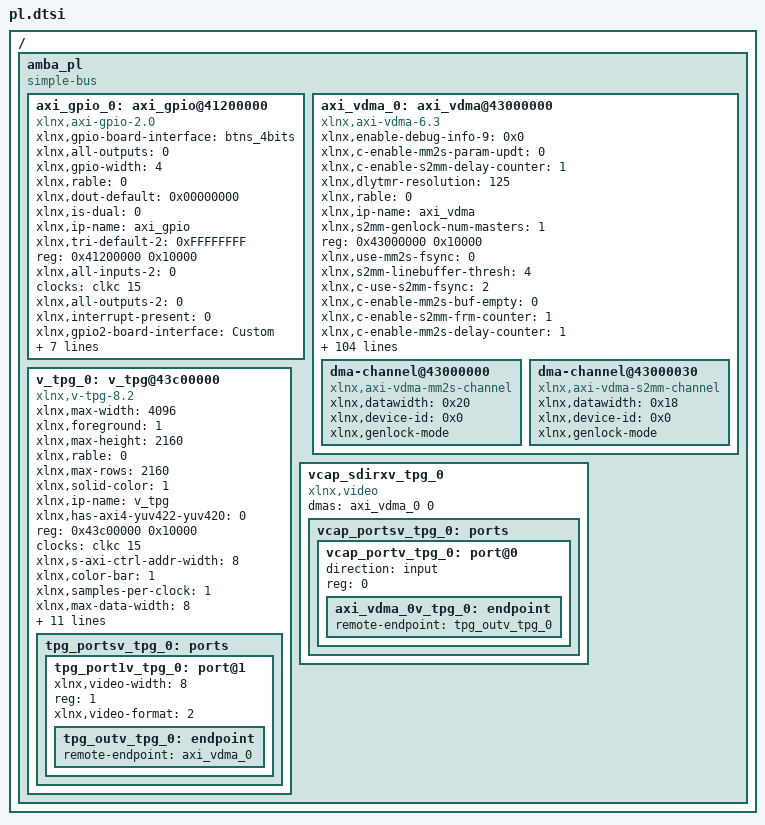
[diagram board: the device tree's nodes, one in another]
/ {
	amba_pl: amba_pl {
		ranges;
		compatible = "simple-bus";
		#address-cells = <1>;
		#size-cells = <1>;
		axi_gpio_0: axi_gpio@41200000 {
			xlnx,gpio-board-interface = "btns_4bits";
			compatible = "xlnx,axi-gpio-2.0" , "xlnx,xps-gpio-1.00.a";
			xlnx,all-outputs = <0>;
			xlnx,gpio-width = <4>;
			xlnx,rable = <0>;
			xlnx,dout-default = <0x00000000>;
			xlnx,is-dual = <0>;
			xlnx,ip-name = "axi_gpio";
			xlnx,tri-default-2 = <0xFFFFFFFF>;
			reg = <0x41200000 0x10000>;
			xlnx,all-inputs-2 = <0>;
			clocks = <&clkc 15>;
			xlnx,all-outputs-2 = <0>;
			xlnx,interrupt-present = <0>;
			xlnx,gpio2-board-interface = "Custom";
			xlnx,edk-iptype = "PERIPHERAL";
			xlnx,dout-default-2 = <0x00000000>;
			xlnx,gpio2-width = <32>;
			status = "okay";
			clock-names = "s_axi_aclk";
			xlnx,use-board-flow;
			xlnx,tri-default = <0xFFFFFFFF>;
			xlnx,name = "axi_gpio_0";
			xlnx,all-inputs = <1>;
		};
		axi_vdma_0: axi_vdma@43000000 {
			xlnx,enable-debug-info-9 = <0x0>;
			xlnx,c-enable-mm2s-param-updt = <0>;
			xlnx,c-enable-s2mm-delay-counter = <1>;
			xlnx,dlytmr-resolution = <125>;
			xlnx,rable = <0>;
			xlnx,ip-name = "axi_vdma";
			xlnx,s2mm-genlock-num-masters = <1>;
			reg = <0x43000000 0x10000>;
			xlnx,use-mm2s-fsync = <0>;
			xlnx,s2mm-linebuffer-thresh = <4>;
			xlnx,c-use-s2mm-fsync = <2>;
			xlnx,c-enable-mm2s-buf-empty = <0>;
			xlnx,c-enable-s2mm-frm-counter = <1>;
			xlnx,c-enable-mm2s-delay-counter = <1>;
			xlnx,c-dlytmr-resolution = <125>;
			xlnx,c-enable-s2mm-buf-full = <0>;
			xlnx,dynamic-resolution = <1>;
			xlnx,s2mm-sof-enable = <0x1>;
			xlnx,mm2s-genlock-num-masters = <1>;
			xlnx,c-s2mm-genlock-num-masters = <1>;
			xlnx,c-enable-s2mm-fsync-out = <0>;
			xlnx,mm2s-linebuffer-thresh = <4>;
			xlnx,c-use-mm2s-fsync = <0>;
			xlnx,c-s2mm-linebuffer-thresh = <4>;
			xlnx,c-enable-mm2s-frm-counter = <1>;
			compatible = "xlnx,axi-vdma-6.3" , "xlnx,axi-vdma-1.00.a";
			xlnx,c-m-axis-mm2s-tdata-width = <32>;
			xlnx,c-enable-all = <0>;
			xlnx,s2mm-max-burst-length = <8>;
			xlnx,c-dynamic-resolution = <1>;
			xlnx,c-enable-s2mm-rst-out = <0>;
			xlnx,mm2s-sof-enable = <1>;
			xlnx,include-s2mm-dre = <0x0>;
			xlnx,c-s2mm-sof-enable = <1>;
			xlnx,c-enable-mm2s-fsync-out = <0>;
			xlnx,c-mm2s-genlock-num-masters = <1>;
			xlnx,c-mm2s-linebuffer-thresh = <4>;
			xlnx,c-enable-tstvec = <0>;
			xlnx,mm2s-max-burst-length = <8>;
			xlnx,c-s2mm-max-burst-length = <8>;
			status = "okay";
			xlnx,c-enable-mm2s-rst-out = <0>;
			xlnx,include-mm2s-dre = <0x0>;
			xlnx,c-include-s2mm-dre = <0>;
			xlnx,c-mm2s-sof-enable = <1>;
			xlnx,name = "axi_vdma_0";
			xlnx,c-enable-s2mm-frmstr-reg = <0>;
			xlnx,c-include-sg = <0>;
			xlnx,flush-on-fsync = <0x1>;
			xlnx,c-m-axi-s2mm-data-width = <64>;
			xlnx,c-enable-s2mm-sts-reg = <0>;
			xlnx,include-s2mm-sf = <1>;
			xlnx,c-mm2s-max-burst-length = <8>;
			xlnx,s2mm-linebuffer-depth = <0x200>;
			xlnx,include-s2mm = <0x1>;
			xlnx,c-include-mm2s-dre = <0>;
			clocks = <&clkc 15>, <&clkc 15>, <&clkc 15>, <&clkc 15>, <&clkc 15>;
			xlnx,c-enable-mm2s-frmstr-reg = <0>;
			xlnx,enable-debug-info-10 = <0>;
			xlnx,addrwidth = <0x20>;
			xlnx,enable-debug-info-11 = <0>;
			xlnx,enable-debug-info-12 = <0>;
			xlnx,edk-iptype = "PERIPHERAL";
			xlnx,c-flush-on-fsync = <1>;
			xlnx,c-m-axi-mm2s-data-width = <64>;
			xlnx,use-fsync = <1>;
			xlnx,s2mm-genlock-repeat-en = <1>;
			xlnx,enable-vert-flip = <0x0>;
			xlnx,enable-debug-info-13 = <0x0>;
			xlnx,include-mm2s-sf = <0>;
			xlnx,include-internal-genlock = <0x1>;
			xlnx,enable-debug-info-14 = <0x1>;
			xlnx,c-include-s2mm-sf = <1>;
			clock-names = "m_axi_mm2s_aclk" , "m_axi_s2mm_aclk" , "m_axis_mm2s_aclk" , "s_axi_lite_aclk" , "s_axis_s2mm_aclk";
			xlnx,enable-debug-info-15 = <0x1>;
			xlnx,mm2s-linebuffer-depth = <0x200>;
			xlnx,include-mm2s = <0x1>;
			xlnx,c-single-interface = <0>;
			xlnx,c-s2mm-linebuffer-depth = <512>;
			xlnx,c-addr-width = <32>;
			xlnx,c-include-s2mm = <1>;
			xlnx,s2mm-genlock-mode = <0x2>;
			xlnx,c-s-axis-s2mm-tdata-width = <24>;
			xlnx,flush-fsync = <0x1>;
			xlnx,select-xpm = <0>;
			xlnx,s2mm-data-width = <0x40>;
			xlnx,num-fstores = <0x3>;
			xlnx,enable-vidparam-reads = <0x1>;
			xlnx,mm2s-genlock-repeat-en = <0>;
			xlnx,c-use-fsync = <1>;
			xlnx,c-s2mm-genlock-repeat-en = <1>;
			xlnx,c-enable-vert-flip = <0>;
			xlnx,prmry-is-aclk-async = <0>;
			xlnx,c-include-internal-genlock = <1>;
			xlnx,c-include-mm2s-sf = <0>;
			xlnx,s2mm-tdata-width = <0x18>;
			xlnx,enable-vidprmtr-reads = <1>;
			xlnx,c-include-mm2s = <1>;
			xlnx,c-mm2s-linebuffer-depth = <512>;
			xlnx,mm2s-genlock-mode = <0x3>;
			xlnx,enable-debug-info-0 = <0>;
			xlnx,enable-debug-all = <0x0>;
			xlnx,c-s2mm-genlock-mode = <2>;
			xlnx,enable-debug-info-1 = <0x0>;
			xlnx,mm2s-data-width = <0x40>;
			xlnx,enable-debug-info-2 = <0>;
			xlnx,c-enable-s2mm-param-updt = <0>;
			xlnx,c-num-fstores = <3>;
			xlnx,enable-debug-info-3 = <0>;
			xlnx,enable-debug-info-4 = <0>;
			xlnx,c-mm2s-genlock-repeat-en = <0>;
			xlnx,enable-debug-info-5 = <0x0>;
			xlnx,c-prmry-is-aclk-async = <0>;
			xlnx,mm2s-tdata-width = <0x20>;
			xlnx,enable-debug-info-6 = <0x1>;
			xlnx,enable-debug-info-7 = <0x1>;
			xlnx,c-enable-vidprmtr-reads = <1>;
			xlnx,use-s2mm-fsync = <2>;
			xlnx,enable-debug-info-8 = <0>;
			xlnx,c-mm2s-genlock-mode = <3>;
			dma-channel@43000000 {
				xlnx,datawidth = <0x20>;
				xlnx,device-id = <0x0>;
				compatible = "xlnx,axi-vdma-mm2s-channel";
				xlnx,genlock-mode;
			};
			dma-channel@43000030 {
				xlnx,datawidth = <0x18>;
				xlnx,device-id = <0x0>;
				compatible = "xlnx,axi-vdma-s2mm-channel";
				xlnx,genlock-mode;
			};
		};
		v_tpg_0: v_tpg@43c00000 {
			compatible = "xlnx,v-tpg-8.2" , "xlnx,v-tpg-8.0";
			xlnx,max-width = <4096>;
			xlnx,foreground = <1>;
			xlnx,max-height = <2160>;
			xlnx,rable = <0>;
			xlnx,max-rows = <2160>;
			xlnx,solid-color = <1>;
			xlnx,ip-name = "v_tpg";
			xlnx,has-axi4-yuv422-yuv420 = <0>;
			reg = <0x43c00000 0x10000>;
			clocks = <&clkc 15>;
			xlnx,s-axi-ctrl-addr-width = <8>;
			xlnx,color-bar = <1>;
			xlnx,samples-per-clock = <1>;
			xlnx,max-data-width = <8>;
			xlnx,has-axi4s-slave = <0>;
			xlnx,ppc = <1>;
			xlnx,max-cols = <4096>;
			xlnx,edk-iptype = "PERIPHERAL";
			status = "okay";
			clock-names = "ap_clk";
			xlnx,zone-plate = <1>;
			xlnx,num-video-components = <3>;
			xlnx,s-axi-ctrl-data-width = <32>;
			xlnx,ramp = <1>;
			xlnx,color-sweep = <1>;
			xlnx,display-port = <1>;
			xlnx,name = "v_tpg_0";
			tpg_portsv_tpg_0: ports {
				#address-cells = <1>;
				#size-cells = <0>;
				tpg_port1v_tpg_0: port@1 {
					xlnx,video-width = <8>;
					reg = <1>;
					xlnx,video-format = <2>;
					tpg_outv_tpg_0: endpoint {
						remote-endpoint = <&axi_vdma_0>;
					};
				};
			};
		};
		vcap_sdirxv_tpg_0 {
			compatible = "xlnx,video";
			dmas = <&axi_vdma_0 0>;
			dma-names = "port0";
			vcap_portsv_tpg_0: ports {
				#address-cells = <1>;
				#size-cells = <0>;
				vcap_portv_tpg_0: port@0 {
					direction = "input";
					reg = <0>;
					axi_vdma_0v_tpg_0: endpoint {
						remote-endpoint = <&tpg_outv_tpg_0>;
					};
				};
			};
		};
	};
};
